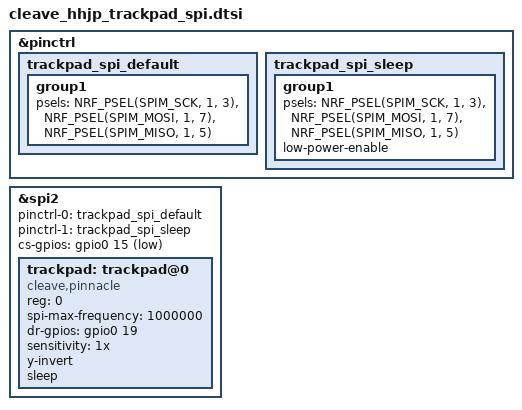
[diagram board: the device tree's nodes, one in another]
/* SPDX-License-Identifier: MIT */

&pinctrl {
	trackpad_spi_default: trackpad_spi_default {
		group1 {
			/* D17/SCK, D19/SI, D18/SO on each local XIAO. */
			psels = <NRF_PSEL(SPIM_SCK, 1, 3)>,
				<NRF_PSEL(SPIM_MOSI, 1, 7)>,
				<NRF_PSEL(SPIM_MISO, 1, 5)>;
		};
	};

	trackpad_spi_sleep: trackpad_spi_sleep {
		group1 {
			psels = <NRF_PSEL(SPIM_SCK, 1, 3)>,
				<NRF_PSEL(SPIM_MOSI, 1, 7)>,
				<NRF_PSEL(SPIM_MISO, 1, 5)>;
			low-power-enable;
		};
	};
};

&spi2 {
	status = "okay";
	pinctrl-0 = <&trackpad_spi_default>;
	pinctrl-1 = <&trackpad_spi_sleep>;
	pinctrl-names = "default", "sleep";
	cs-gpios = <&gpio0 15 GPIO_ACTIVE_LOW>; /* D11/SS. */

	trackpad: trackpad@0 {
		compatible = "cleave,pinnacle";
		reg = <0>;
		spi-max-frequency = <1000000>;
		dr-gpios = <&gpio0 19 GPIO_ACTIVE_HIGH>; /* D12/DR. */
		sensitivity = "1x";
		y-invert; /* Match the installed pad's vertical direction to host coordinates. */
		sleep;
		/* Primary taps and the hardware secondary-tap zone are enabled. */
	};
};

